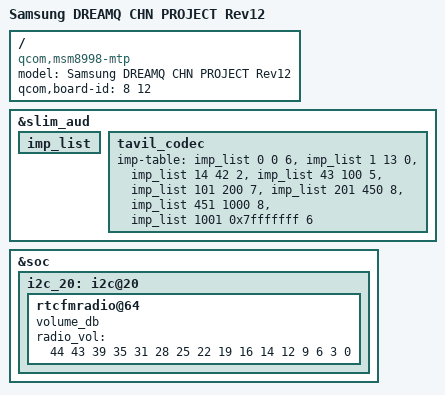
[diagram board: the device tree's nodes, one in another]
/* Copyright (c) 2016, The Linux Foundation. All rights reserved.
 *
 * This program is free software; you can redistribute it and/or modify
 * it under the terms of the GNU General Public License version 2 and
 * only version 2 as published by the Free Software Foundation.
 *
 * This program is distributed in the hope that it will be useful,
 * but WITHOUT ANY WARRANTY; without even the implied warranty of
 * MERCHANTABILITY or FITNESS FOR A PARTICULAR PURPOSE.  See the
 * GNU General Public License for more details.
 */


/dts-v1/;

#include "../qcom/msm8998-v2.1.dtsi"
#include "../qcom/msm8998-mtp.dtsi"
#include "msm8998-sec-common.dtsi"
#include "msm8998-sec-dreamq-common.dtsi"
#include "msm8998-sec-dreamq-common-pm.dtsi"
#include "battery-data-dreamq-r07.dtsi"
#include "msm8998-sec-dreamq-r12.dtsi"
#include "msm8998-sec-dreamq-pm-r02.dtsi"
/ {
	model = "Samsung DREAMQ CHN PROJECT Rev12";
	compatible = "qcom,msm8998-mtp", "qcom,msm8998", "qcom,mtp";
	qcom,board-id = <8 12>;

};

&slim_aud {
	imp_list: imp_list {
		#list-imp-cells = <3>;
	};

	tavil_codec {
		imp-table = <&imp_list 0 0 6>,
				 <&imp_list 1 13 0>,
				 <&imp_list 14 42 2>,
				 <&imp_list 43 100 5>,
				 <&imp_list 101 200 7>,
				 <&imp_list 201 450 8>,
				 <&imp_list 451 1000 8>,
				 <&imp_list 1001 0x7fffffff 6>;
	};
};

&soc {
	i2c_20: i2c@20{ /* FM Radio (Richwave) */
		rtcfmradio@64 {
			volume_db;
			radio_vol = <44 43 39 35 31 28 25 22
				19 16 14 12 9 6 3 0>;
		};
	};
};
